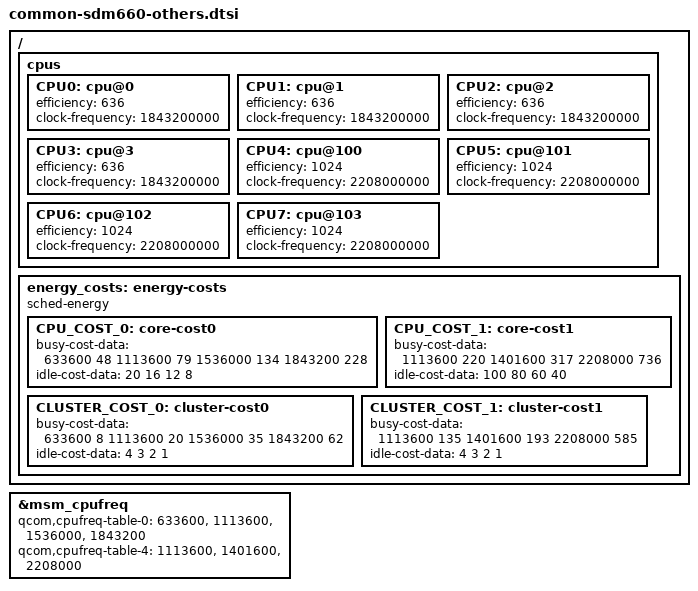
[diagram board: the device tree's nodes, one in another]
/* Copyright (c) 2016-2019, The Linux Foundation. All rights reserved.
 *
 * This program is free software; you can redistribute it and/or modify
 * it under the terms of the GNU General Public License version 2 and
 * only version 2 as published by the Free Software Foundation.
 *
 * This program is distributed in the hope that it will be useful,
 * but WITHOUT ANY WARRANTY; without even the implied warranty of
 * MERCHANTABILITY or FITNESS FOR A PARTICULAR PURPOSE.  See the
 * GNU General Public License for more details.
 */

/* sdm660.dtsi lavender/jasmine/wayne specific diff */
/ {
	cpus {
		CPU0: cpu@0 {
			efficiency = <636>;
			clock-frequency = <1843200000>;
		};

		CPU1: cpu@1 {
			efficiency = <636>;
			clock-frequency = <1843200000>;
		};

		CPU2: cpu@2 {
			efficiency = <636>;
			clock-frequency = <1843200000>;
		};

		CPU3: cpu@3 {
			efficiency = <636>;
			clock-frequency = <1843200000>;
		};

		CPU4: cpu@100 {
			efficiency = <1024>;
			clock-frequency = <2208000000>;
		};

		CPU5: cpu@101 {
			efficiency = <1024>;
			clock-frequency = <2208000000>;
		};

		CPU6: cpu@102 {
			efficiency = <1024>;
			clock-frequency = <2208000000>;
		};

		CPU7: cpu@103 {
			efficiency = <1024>;
			clock-frequency = <2208000000>;
		};
	};

	energy_costs: energy-costs {
		compatible = "sched-energy";

		CPU_COST_0: core-cost0 {
			busy-cost-data = <
				 633600  48
				1113600  79
				1536000 134
				1843200 228
			>;
			idle-cost-data = <
				20 16 12 8
			>;
		};

		CPU_COST_1: core-cost1 {
			busy-cost-data = <
				1113600 220
				1401600 317
				2208000 736
			>;
			idle-cost-data = <
				100 80 60 40
			>;
		};

		CLUSTER_COST_0: cluster-cost0 {
			busy-cost-data = <
				 633600 8
				1113600 20
				1536000 35
				1843200 62
			>;
			idle-cost-data = <
				4 3 2 1
			>;
		};

		CLUSTER_COST_1: cluster-cost1 {
			busy-cost-data = <
				1113600 135
				1401600 193
				2208000 585
			>;
			idle-cost-data = <
				4 3 2 1
			>;
		};
	};
};

/* Efficient freq based on result from freqbench */
&msm_cpufreq {
	qcom,cpufreq-table-0 =
		< 633600  >,
		< 1113600 >,
		< 1536000 >,
		< 1843200 >;

	qcom,cpufreq-table-4 =
		< 1113600 >,
		< 1401600 >,
		< 2208000 >;
};
